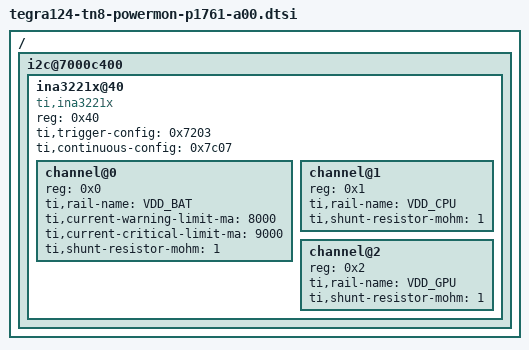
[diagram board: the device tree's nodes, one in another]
/*
 * Power monitor devices for the E1784
 *
 * Copyright (c) 2014, NVIDIA CORPORATION.  All rights reserved.
 *
 * This program is free software; you can redistribute it and/or modify
 * it under the terms of the GNU General Public License as published by
 * the Free Software Foundation; either version 2 of the License, or
 * (at your option) any later version.
 *
 * This program is distributed in the hope that it will be useful, but WITHOUT
 * ANY WARRANTY; without even the implied warranty of MERCHANTABILITY or
 * FITNESS FOR A PARTICULAR PURPOSE.  See the GNU General Public License for
 * more details.
 */

/ {
	i2c@7000c400 {
		ina3221x@40 {
		compatible = "ti,ina3221x";
			reg = <0x40>;
			ti,trigger-config = <0x7203>;
			ti,continuous-config = <0x7c07>;
			#address-cells = <1>;
			#size-cells = <0>;

			channel@0 {
				reg = <0x0>;
				ti,rail-name = "VDD_BAT";
				ti,current-warning-limit-ma = <8000>;
				ti,current-critical-limit-ma = <9000>;
				ti,shunt-resistor-mohm = <1>;
			};

			channel@1 {
				reg = <0x1>;
				ti,rail-name = "VDD_CPU";
				ti,shunt-resistor-mohm = <1>;
			};

			channel@2 {
				reg = <0x2>;
				ti,rail-name = "VDD_GPU";
				ti,shunt-resistor-mohm = <1>;
			};
		};
	};
};
